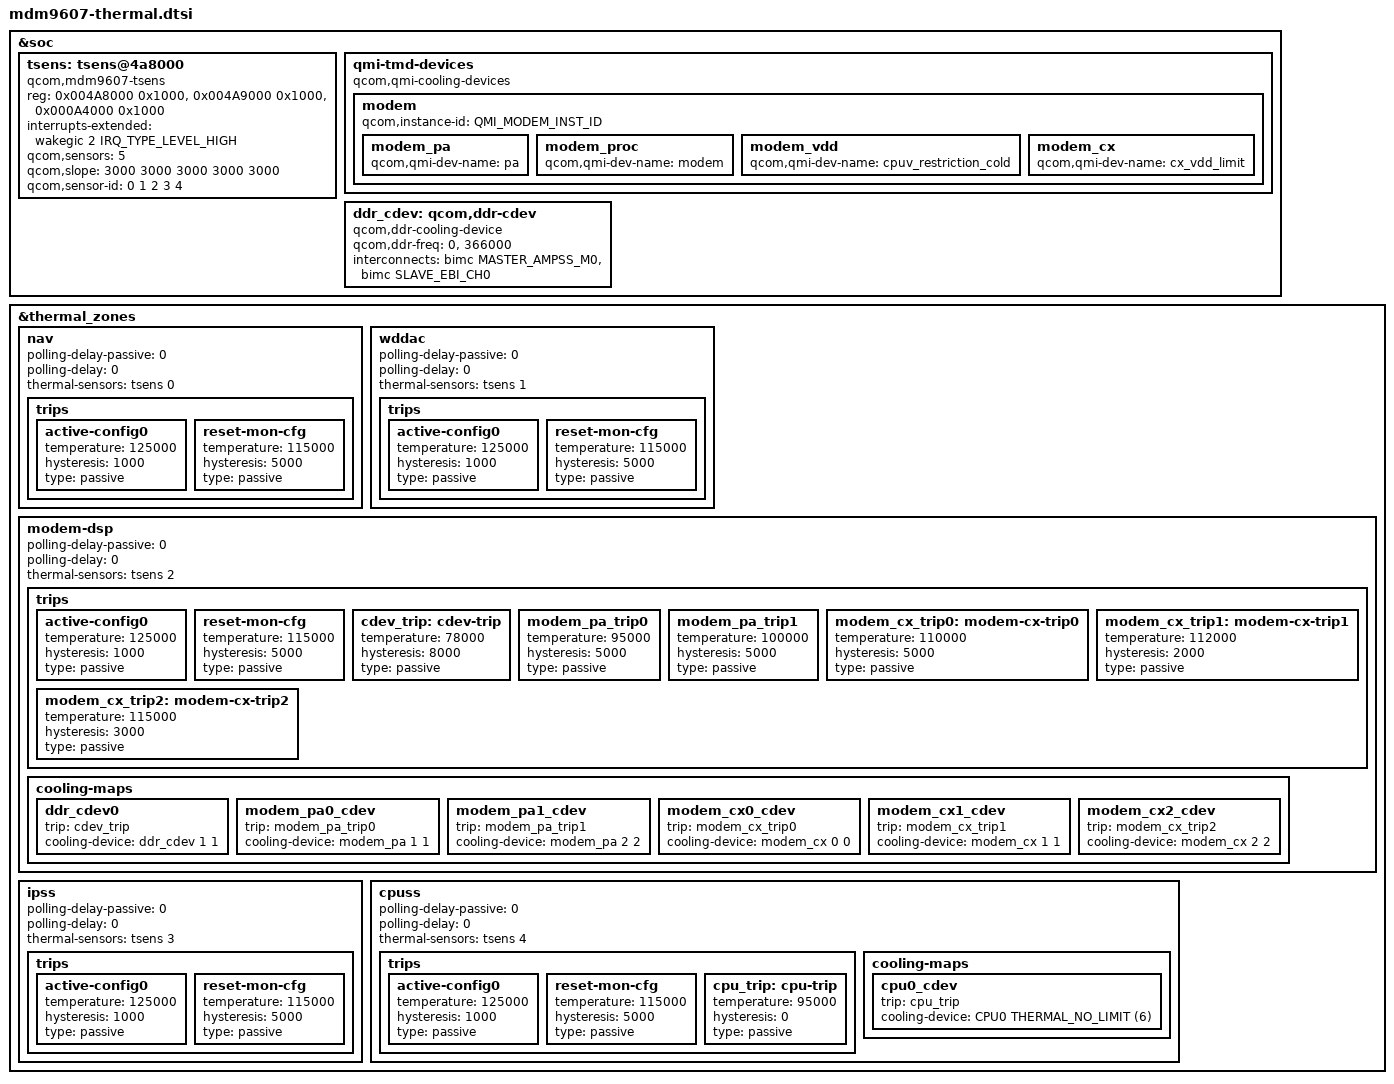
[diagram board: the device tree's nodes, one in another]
#include <dt-bindings/thermal/thermal.h>
#include <dt-bindings/thermal/thermal_qti.h>

&soc {
	 tsens: tsens@4a8000 {
		compatible = "qcom,mdm9607-tsens";
		reg = <0x004A8000 0x1000>,
			<0x004A9000 0x1000>,
			<0x000A4000  0x1000>;
		reg-names ="tsens_srot_physical",
			"tsens_tm_physical",
			"tsens_eeprom_physical";
		interrupts-extended = <&wakegic 2 IRQ_TYPE_LEVEL_HIGH>;
		interrupt-names = "tsens-upper-lower";
		qcom,sensors = <5>;
		qcom,slope = <3000 3000 3000 3000 3000>;
		qcom,sensor-id = <0 1 2 3 4>;
		#thermal-sensor-cells = <1>;
	};

	qmi-tmd-devices {
		compatible = "qcom,qmi-cooling-devices";

		modem {
			qcom,instance-id = <QMI_MODEM_INST_ID>;

		modem_pa: modem_pa {
				qcom,qmi-dev-name = "pa";
				#cooling-cells = <2>;
			};

		modem_proc: modem_proc {
				qcom,qmi-dev-name = "modem";
				#cooling-cells = <2>;
			};

		modem_vdd: modem_vdd {
				qcom,qmi-dev-name = "cpuv_restriction_cold";
				#cooling-cells = <2>;
			};

		modem_cx: modem_cx {
				qcom,qmi-dev-name = "cx_vdd_limit";
				#cooling-cells = <2>;
			};
		};
	};

	ddr_cdev: qcom,ddr-cdev {
		compatible = "qcom,ddr-cooling-device";
		#cooling-cells = <2>;
		qcom,ddr-freq = <0>,
				<366000>;
		interconnects = <&bimc MASTER_AMPSS_M0 &bimc SLAVE_EBI_CH0>;
	};
};

&thermal_zones {
	nav {
		polling-delay-passive = <0>;
		polling-delay = <0>;
		thermal-sensors = <&tsens 0>;
		trips {
			active-config0 {
				temperature = <125000>;
				hysteresis = <1000>;
				type = "passive";
			};

			reset-mon-cfg {
				temperature = <115000>;
				hysteresis = <5000>;
				type = "passive";
			};
		};
	};

	wddac {
		polling-delay-passive = <0>;
		polling-delay = <0>;
		thermal-sensors = <&tsens 1>;
		trips {
			active-config0 {
				temperature = <125000>;
				hysteresis = <1000>;
				type = "passive";
			};

			reset-mon-cfg {
				temperature = <115000>;
				hysteresis = <5000>;
				type = "passive";
			};
		};
	};

	modem-dsp {
		polling-delay-passive = <0>;
		polling-delay = <0>;
		thermal-sensors = <&tsens 2>;
		trips {
			active-config0 {
				temperature = <125000>;
				hysteresis = <1000>;
				type = "passive";
			};

			reset-mon-cfg {
				temperature = <115000>;
				hysteresis = <5000>;
				type = "passive";
			};

			cdev_trip: cdev-trip {
				temperature = <78000>;
				hysteresis = <8000>;
				type = "passive";
			};

			modem_pa_trip0: modem_pa_trip0 {
				temperature = <95000>;
				hysteresis = <5000>;
				type = "passive";
			};

			modem_pa_trip1: modem_pa_trip1 {
				temperature = <100000>;
				hysteresis = <5000>;
				type = "passive";
			};

			modem_cx_trip0: modem-cx-trip0  {
				temperature = <110000>;
				hysteresis = <5000>;
				type = "passive";
			};

			modem_cx_trip1: modem-cx-trip1 {
				temperature = <112000>;
				hysteresis = <2000>;
				type = "passive";
			};

			modem_cx_trip2: modem-cx-trip2 {
				temperature = <115000>;
				hysteresis = <3000>;
				type = "passive";
			};

		};

		cooling-maps {
			ddr_cdev0 {
				trip = <&cdev_trip>;
				cooling-device = <&ddr_cdev 1 1>;
			};

			modem_pa0_cdev {
				trip = <&modem_pa_trip0>;
				cooling-device = <&modem_pa 1 1>;
			};

			modem_pa1_cdev {
				trip = <&modem_pa_trip1>;
				cooling-device = <&modem_pa 2 2>;
			};

			modem_cx0_cdev {
				trip = <&modem_cx_trip0>;
				cooling-device = <&modem_cx 0 0>;
			};

			modem_cx1_cdev {
				trip = <&modem_cx_trip1>;
				cooling-device = <&modem_cx 1 1>;
			};

			modem_cx2_cdev {
				trip = <&modem_cx_trip2>;
				cooling-device = <&modem_cx 2 2>;
			};
		};

	};

	ipss {
		polling-delay-passive = <0>;
		polling-delay = <0>;
		thermal-sensors = <&tsens 3>;
		trips {
		active-config0 {
				temperature = <125000>;
				hysteresis = <1000>;
				type = "passive";
			};

			reset-mon-cfg {
				temperature = <115000>;
				hysteresis = <5000>;
				type = "passive";
			};
		};
	};

	cpuss {
		polling-delay-passive = <0>;
		polling-delay = <0>;
		thermal-sensors = <&tsens 4>;
		trips {
			active-config0 {
				temperature = <125000>;
				hysteresis = <1000>;
				type = "passive";
			};

			reset-mon-cfg {
				temperature = <115000>;
				hysteresis = <5000>;
				type = "passive";
			};

			cpu_trip:cpu-trip  {
				temperature = <95000>;
				hysteresis = <0>;
				type = "passive";
			};

		};

		cooling-maps {
			cpu0_cdev {
				trip = <&cpu_trip>;
				cooling-device =
					<&CPU0 THERMAL_NO_LIMIT
					(6)>;
			};
		};

	};

};
